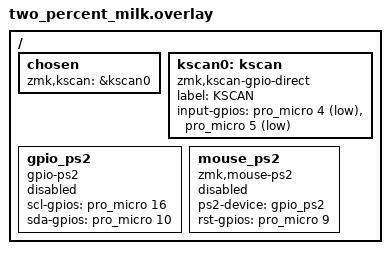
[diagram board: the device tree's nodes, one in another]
/*
 * Copyright (c) 2022 The ZMK Contributors
 *
 * SPDX-License-Identifier: MIT
 */

/ {
    chosen {
        zmk,kscan = &kscan0;
    };

    kscan0: kscan {
        compatible = "zmk,kscan-gpio-direct";

        label = "KSCAN";

        input-gpios
            = <&pro_micro 4 (GPIO_ACTIVE_LOW | GPIO_PULL_UP)>
            , <&pro_micro 5 (GPIO_ACTIVE_LOW | GPIO_PULL_UP)>
            ;

    };

};

// The PS/2 GPIO and mouse drivers.
/ {
    gpio_ps2: gpio_ps2 {
		status = "disabled";
        compatible = "gpio-ps2";

        // The two bottom left pins of the nice!nano (when it is facing down)
        scl-gpios = <&pro_micro 16 0>;
        sda-gpios = <&pro_micro 10 0>;
    };
};

/ {
    mouse_ps2: mouse_ps2 {
		status = "disabled";
        compatible = "zmk,mouse-ps2";
        ps2-device = <&gpio_ps2>;

        // Uncomment this if you have an extra free pin and
        // want the controller to perform the Power-On-Reset
        // instead of using a reset circuit.
        //
        // The bottom right pin of the nice!nano (when it is facing down)
        rst-gpios = <&pro_micro 9 0>;
    };
};
